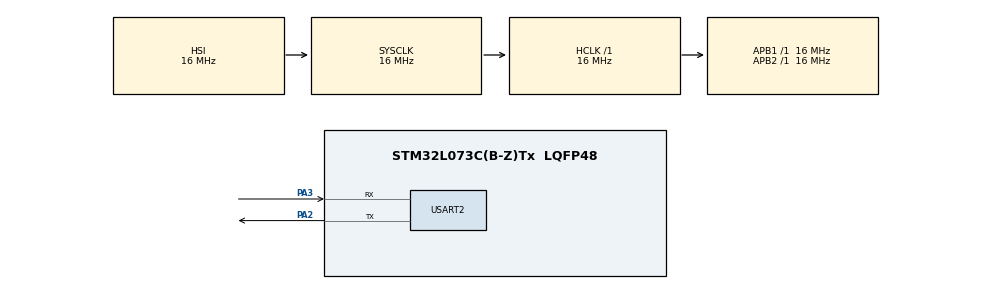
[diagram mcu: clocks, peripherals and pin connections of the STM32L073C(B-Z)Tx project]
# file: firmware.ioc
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Mcu.Family=STM32L0
Mcu.Name=STM32L073C(B-Z)Tx
Mcu.Package=LQFP48
NVIC.RTC_IRQn=true\:0\:0\:false\:false\:true\:true\:true\:true
PA13.Mode=Serial_Wire
PA13.Signal=SYS_SWDIO
PA14.Mode=Serial_Wire
PA14.Signal=SYS_SWCLK
PA2.Mode=Asynchronous
PA2.Signal=USART2_TX
PA3.Mode=Asynchronous
PA3.Signal=USART2_RX
PC14-OSC32_IN.Mode=LSE-External-Oscillator
PC14-OSC32_IN.Signal=RCC_OSC32_IN
PC15-OSC32_OUT.Mode=LSE-External-Oscillator
PC15-OSC32_OUT.Signal=RCC_OSC32_OUT
ProjectManager.HeapSize=0x200
ProjectManager.StackSize=0x400
ProjectManager.TargetToolchain=CMake
RCC.AHBFreq_Value=16000000
RCC.APB1Freq_Value=16000000
RCC.APB1TimFreq_Value=16000000
RCC.APB2Freq_Value=16000000
RCC.APB2TimFreq_Value=16000000
RCC.HCLKFreq_Value=16000000
RCC.HSE_VALUE=8000000
RCC.HSI16_VALUE=16000000
RCC.HSI48_VALUE=48000000
RCC.HSI_VALUE=16000000
RCC.MSI_VALUE=2097000
RCC.RTCClockSelection=RCC_RTCCLKSOURCE_LSE
RCC.RTCClockSelectionVirtual=RCC_RTCCLKSOURCE_LSE
RCC.SYSCLKFreq_VALUE=16000000
RCC.SYSCLKSource=RCC_SYSCLKSOURCE_HSI
RCC.VCOOutputFreq_Value=48000000
RTC.Alarm-Alarm\ A=RTC_ALARM_A
RTC.Alarm_B-Alarm\ B=RTC_ALARM_B
RTC.Format=RTC_FORMAT_BIN
RTC.WakeUpClock-WakeUp=RTC_WAKEUPCLOCK_CK_SPRE_16BITS
RTC.WakeUpCounter-WakeUp=1
USART2.VirtualMode-Asynchronous=VM_ASYNC
VP_RTC_VS_RTC_Activate.Mode=RTC_Enabled
VP_RTC_VS_RTC_Alarm_A_Intern.Mode=Alarm A
VP_RTC_VS_RTC_Alarm_B_Intern.Mode=Alarm B
VP_RTC_VS_RTC_Calendar.Mode=RTC_Calendar
VP_RTC_VS_RTC_WakeUp_intern.Mode=WakeUp
board=custom

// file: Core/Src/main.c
/* USER CODE BEGIN Header */
/**
  ******************************************************************************
  * @file           : main.c
  * @brief          : Main program body
  ******************************************************************************
  * @attention
  *
  * Copyright (c) 2026 STMicroelectronics.
  * All rights reserved.
  *
  * This software is licensed under terms that can be found in the LICENSE file
  * in the root directory of this software component.
  * If no LICENSE file comes with this software, it is provided AS-IS.
  *
  ******************************************************************************
  */
/* USER CODE END Header */
#include "main.h"
#include "stm32l0xx_hal_rtc.h"

/* USER CODE BEGIN Includes */
#include <stdint.h>
#include <string.h>
#include <stdio.h>
#include <stdbool.h>
/* USER CODE END Includes */

/* USER CODE BEGIN PTD */
typedef enum
{
  MODE_CLOCK,
  MODE_ALARM,
  MODE_TIMER,
  MODE_WATER,
  MODE_ADJUST,
  MODE_COUNT // not really a "mode", it is used to increment modes easily
} Mode;
typedef enum
{
  ALM = RTC_ALARM_A,
  SIG = RTC_ALARM_B
} AlarmSelect;
typedef enum
{
  AL_MODE_NONE,
  AL_MODE_ALM,
  AL_MODE_SIG,
  AL_MODE_ALM_SIG
} AlarmMode;
typedef struct
{
  uint8_t hour;
  uint8_t min;
} alarmTime;
typedef struct
{
  uint16_t current_intake;
  uint16_t goal;
  bool hit_daily;
} water_system;
typedef enum
{
  CLK_ADJUST_SECONDS,
  CLK_ADJUST_HOURS,
  CLK_ADJUST_MINUTES,
  CLK_ADJUST_MONTH,
  CLK_ADJUST_DATE,
  CLK_ADJUST_WEEKDAY,
  CLK_ADJUST_COUNT
} clock_adjust;
typedef enum
{
  ALM_ADJUST_HOURS,
  ALM_ADJUST_MINUTES,
  ALM_ADJUST_COUNT,
} alarm_adjust;
/* USER CODE END PTD */

/* USER CODE BEGIN PD */
#define EVT_RTC   (1u << 0)
#define EVT_BTN_A (1u << 1) // LIGHT button on the watch
#define EVT_BTN_B (1u << 2) // MODE  button on the watch
#define EVT_BTN_C (1u << 3) // 24HR  button on the watch
#define EVT_ALARM (1u << 4)
#define EVT_TIMER (1u << 5)
/* USER CODE END PD */

RTC_HandleTypeDef hrtc;

UART_HandleTypeDef huart2;

volatile uint8_t events = 0;

Mode mode = MODE_CLOCK;
AlarmMode alarm_mode;

alarmTime alarm;
alarm.hour = 7;
alarm.minute = 0;

water_system water;
water.current_intake = 0;
water.goal = 2000;
water.hit_daily = false;

void SystemClock_Config(void);
static void MX_GPIO_Init(void);
static void MX_RTC_Init(void);
static void MX_USART2_UART_Init(void);
/* USER CODE BEGIN PFP */
void Set_Time (uint8_t hr, uint8_t min, uint8_t sec);
void Set_Date (uint8_t year, uint8_t month, uint8_t date, uint8_t day);
void Set_Alarm (uint8_t hr, uint8_t min, uint8_t sec, uint8_t date);

void Get_TimeDate(char *time, char *date);

void HAL_RTC_AlarmAEventCallback(RTC_HandleTypeDef *hrtc);
void HAL_RTCEx_WakeUpTimerEventCallback(RTC_HandleTypeDef *hrtc);

void Update_Display();

int _write(int file, char *ptr, int len);
/* USER CODE END PFP */

/* USER CODE BEGIN 0 */

// Set functions

void Set_Time (uint8_t hr, uint8_t min, uint8_t sec)
{
	RTC_TimeTypeDef sTime = {0};
	sTime.Hours = hr;
	sTime.Minutes = min;
	sTime.Seconds = sec;
	sTime.DayLightSaving = RTC_DAYLIGHTSAVING_NONE;
	sTime.StoreOperation = RTC_STOREOPERATION_RESET;
	if (HAL_RTC_SetTime(&hrtc, &sTime, RTC_FORMAT_BIN) != HAL_OK)
	{
		Error_Handler();
	}
}

void Set_Date (uint8_t year, uint8_t month, uint8_t date, uint8_t day)  // monday = 1
{
	RTC_DateTypeDef sDate = {0};
	sDate.Year = year;
	sDate.Month = month;
	sDate.Date = date;
	sDate.WeekDay = day;
	if (HAL_RTC_SetDate(&hrtc, &sDate, RTC_FORMAT_BIN) != HAL_OK)
	{
		Error_Handler();
	}

	HAL_RTCEx_BKUPWrite(&hrtc, RTC_BKP_DR1, 0x2345);  // backup register
}

void Set_Alarm (uint8_t hr, uint8_t min, AlarmSelect alm)
{
	RTC_AlarmTypeDef sAlarm = {0};
	sAlarm.AlarmTime.Hours = hr;
	sAlarm.AlarmTime.Minutes = min;

	sAlarm.AlarmMask = RTC_ALARMMASK_DATEWEEKDAY;
	sAlarm.Alarm = alm;

	if (HAL_RTC_SetAlarm_IT(&hrtc, &sAlarm, RTC_FORMAT_BIN) != HAL_OK)
	{
		Error_Handler();
	}
}

// Get funtions
void Get_TimeDate(char *time, char *date)
{
  RTC_TimeTypeDef gTime;
  RTC_DateTypeDef gDate;

  /* Get the RTC current Time */
  HAL_RTC_GetTime(&hrtc, &gTime, RTC_FORMAT_BIN);
  /* Get the RTC current Date */
  HAL_RTC_GetDate(&hrtc, &gDate, RTC_FORMAT_BIN);

  /* Display time Format: hh:mm:ss */
  sprintf((char*)time,"%02d:%02d:%02d",gTime.Hours, gTime.Minutes, gTime.Seconds);

  /* Display date Format: dd-mm-yyyy */
  sprintf((char*)date,"%02d-%02d-%2d",gDate.Date, gDate.Month, 2000 + gDate.Year);
}

// Interrupts
void HAL_RTC_AlarmAEventCallback(RTC_HandleTypeDef *hrtc)
{
  events |= EVT_ALARM;
}

void HAL_RTCEx_WakeUpTimerEventCallback(RTC_HandleTypeDef *hrtc)
{
  events |= EVT_RTC;
}

// Update display
void Update_Display() {
  if (mode == MODE_CLOCK) {
    char timeData[10];
    char dateData[15];
    printf("-- UPDATE (CLK) --\n");
    Get_TimeDate(timeData, dateData);
    printf("%s\n", timeData);
    printf("%s\n", dateData);
    printf("-- END UPDATE --\n");
  }
  else if (mode == MODE_ALARM) {
    printf("-- UPDATE (ALM) --\n")
    printf("%02d:%02d\n", alarm.hour, alarm.min);
    printf("ALM state: %d", alarm_mode);
    printf("-- END UPDATE --\n");
  }
  else if (mode == MODE_TIMER) {
    printf("-- UPDATE (TIM) --\n");
    // TODO: implement the timer in CubeMX
    printf("-- END UPDATE --\n");
  }
  else if (mode == MODE_WATER) {
    printf("-- UPDATE (WAT) --\n")
    printf("Current: %dml\n", water.current_intake)
    printf("Goal: %dml\n", water.goal)
    printf("Hit goal?: %d\n", water.hit_daily)
    printf("-- END UPDATE --\n");
  }
}

// _write
int _write(int file, char *ptr, int len)
{
    HAL_UART_Transmit(&huart2, (uint8_t *)ptr, len, HAL_MAX_DELAY);
    return len;
}
/* USER CODE END 0 */

int main(void)
{

  /* MCU Configuration--------------------------------------------------------*/

  /* Reset of all peripherals, Initializes the Flash interface and the Systick. */
  HAL_Init();

  /* Configure the system clock */
  SystemClock_Config();

  /* Initialize all configured peripherals */
  MX_GPIO_Init();
  MX_RTC_Init();
  MX_USART2_UART_Init();
  /* USER CODE BEGIN 2 */
  if (HAL_RTCEx_BKUPRead(&hrtc, RTC_BKP_DR1) != 0x2345)
  {
    Set_Time(00, 00, 00);
    Set_Date(26, 6, 11, 4);
  }

  /* USER CODE END 2 */

  /* Infinite loop */
  while (1)
  {

    /* USER CODE BEGIN 3 */

    if (events & EVT_ALARM) {
      events &= ~EVT_ALARM;
      printf("alarm!!\n");
    }

    __WFI();
  }
  /* USER CODE END 3 */
}

void SystemClock_Config(void)
{
  RCC_OscInitTypeDef RCC_OscInitStruct = {0};
  RCC_ClkInitTypeDef RCC_ClkInitStruct = {0};
  RCC_PeriphCLKInitTypeDef PeriphClkInit = {0};

  /** Configure the main internal regulator output voltage
  */
  __HAL_PWR_VOLTAGESCALING_CONFIG(PWR_REGULATOR_VOLTAGE_SCALE1);

  /** Configure LSE Drive Capability
  */
  HAL_PWR_EnableBkUpAccess();
  __HAL_RCC_LSEDRIVE_CONFIG(RCC_LSEDRIVE_LOW);

  /** Initializes the RCC Oscillators according to the specified parameters
  * in the RCC_OscInitTypeDef structure.
  */
  RCC_OscInitStruct.OscillatorType = RCC_OSCILLATORTYPE_HSI|RCC_OSCILLATORTYPE_LSE;
  RCC_OscInitStruct.LSEState = RCC_LSE_ON;
  RCC_OscInitStruct.HSIState = RCC_HSI_ON;
  RCC_OscInitStruct.HSICalibrationValue = RCC_HSICALIBRATION_DEFAULT;
  RCC_OscInitStruct.PLL.PLLState = RCC_PLL_NONE;
  if (HAL_RCC_OscConfig(&RCC_OscInitStruct) != HAL_OK)
  {
    Error_Handler();
  }

  /** Initializes the CPU, AHB and APB buses clocks
  */
  RCC_ClkInitStruct.ClockType = RCC_CLOCKTYPE_HCLK|RCC_CLOCKTYPE_SYSCLK
                              |RCC_CLOCKTYPE_PCLK1|RCC_CLOCKTYPE_PCLK2;
  RCC_ClkInitStruct.SYSCLKSource = RCC_SYSCLKSOURCE_HSI;
  RCC_ClkInitStruct.AHBCLKDivider = RCC_SYSCLK_DIV1;
  RCC_ClkInitStruct.APB1CLKDivider = RCC_HCLK_DIV1;
  RCC_ClkInitStruct.APB2CLKDivider = RCC_HCLK_DIV1;

  if (HAL_RCC_ClockConfig(&RCC_ClkInitStruct, FLASH_LATENCY_0) != HAL_OK)
  {
    Error_Handler();
  }
  PeriphClkInit.PeriphClockSelection = RCC_PERIPHCLK_USART2|RCC_PERIPHCLK_RTC;
  PeriphClkInit.Usart2ClockSelection = RCC_USART2CLKSOURCE_PCLK1;
  PeriphClkInit.RTCClockSelection = RCC_RTCCLKSOURCE_LSE;
  if (HAL_RCCEx_PeriphCLKConfig(&PeriphClkInit) != HAL_OK)
  {
    Error_Handler();
  }
}

static void MX_RTC_Init(void)
{

  RTC_TimeTypeDef sTime = {0};
  RTC_DateTypeDef sDate = {0};
  RTC_AlarmTypeDef sAlarm = {0};

  /** Initialize RTC Only
  */
  hrtc.Instance = RTC;
  hrtc.Init.HourFormat = RTC_HOURFORMAT_24;
  hrtc.Init.AsynchPrediv = 127;
  hrtc.Init.SynchPrediv = 255;
  hrtc.Init.OutPut = RTC_OUTPUT_DISABLE;
  hrtc.Init.OutPutRemap = RTC_OUTPUT_REMAP_NONE;
  hrtc.Init.OutPutPolarity = RTC_OUTPUT_POLARITY_HIGH;
  hrtc.Init.OutPutType = RTC_OUTPUT_TYPE_OPENDRAIN;
  if (HAL_RTC_Init(&hrtc) != HAL_OK)
  {
    Error_Handler();
  }

  /** Initialize RTC and set the Time and Date
  */
  sTime.Hours = 0;
  sTime.Minutes = 0;
  sTime.Seconds = 0;
  sTime.DayLightSaving = RTC_DAYLIGHTSAVING_NONE;
  sTime.StoreOperation = RTC_STOREOPERATION_RESET;
  if (HAL_RTC_SetTime(&hrtc, &sTime, RTC_FORMAT_BIN) != HAL_OK)
  {
    Error_Handler();
  }
  sDate.WeekDay = RTC_WEEKDAY_MONDAY;
  sDate.Month = RTC_MONTH_JANUARY;
  sDate.Date = 1;
  sDate.Year = 0;

  if (HAL_RTC_SetDate(&hrtc, &sDate, RTC_FORMAT_BIN) != HAL_OK)
  {
    Error_Handler();
  }

  /** Enable the Alarm A
  */
  sAlarm.AlarmTime.Hours = 0;
  sAlarm.AlarmTime.Minutes = 0;
  sAlarm.AlarmTime.Seconds = 0;
  sAlarm.AlarmTime.SubSeconds = 0;
  sAlarm.AlarmTime.DayLightSaving = RTC_DAYLIGHTSAVING_NONE;
  sAlarm.AlarmTime.StoreOperation = RTC_STOREOPERATION_RESET;
  sAlarm.AlarmMask = RTC_ALARMMASK_NONE;
  sAlarm.AlarmSubSecondMask = RTC_ALARMSUBSECONDMASK_ALL;
  sAlarm.AlarmDateWeekDaySel = RTC_ALARMDATEWEEKDAYSEL_DATE;
  sAlarm.AlarmDateWeekDay = 1;
  sAlarm.Alarm = RTC_ALARM_A;
  if (HAL_RTC_SetAlarm_IT(&hrtc, &sAlarm, RTC_FORMAT_BIN) != HAL_OK)
  {
    Error_Handler();
  }

  /** Enable the Alarm B
  */
  sAlarm.Alarm = RTC_ALARM_B;
  if (HAL_RTC_SetAlarm_IT(&hrtc, &sAlarm, RTC_FORMAT_BIN) != HAL_OK)
  {
    Error_Handler();
  }

  /** Enable the WakeUp
  */
  if (HAL_RTCEx_SetWakeUpTimer_IT(&hrtc, 1, RTC_WAKEUPCLOCK_CK_SPRE_16BITS) != HAL_OK)
  {
    Error_Handler();
  }

}

static void MX_USART2_UART_Init(void)
{

  huart2.Instance = USART2;
  huart2.Init.BaudRate = 115200;
  huart2.Init.WordLength = UART_WORDLENGTH_8B;
  huart2.Init.StopBits = UART_STOPBITS_1;
  huart2.Init.Parity = UART_PARITY_NONE;
  huart2.Init.Mode = UART_MODE_TX_RX;
  huart2.Init.HwFlowCtl = UART_HWCONTROL_NONE;
  huart2.Init.OverSampling = UART_OVERSAMPLING_16;
  huart2.Init.OneBitSampling = UART_ONE_BIT_SAMPLE_DISABLE;
  huart2.AdvancedInit.AdvFeatureInit = UART_ADVFEATURE_NO_INIT;
  if (HAL_UART_Init(&huart2) != HAL_OK)
  {
    Error_Handler();
  }

}

static void MX_GPIO_Init(void)
{

  /* GPIO Ports Clock Enable */
  __HAL_RCC_GPIOC_CLK_ENABLE();
  __HAL_RCC_GPIOA_CLK_ENABLE();

}

void Error_Handler(void)
{
  __disable_irq();
  while (1)
  {
  }
}
